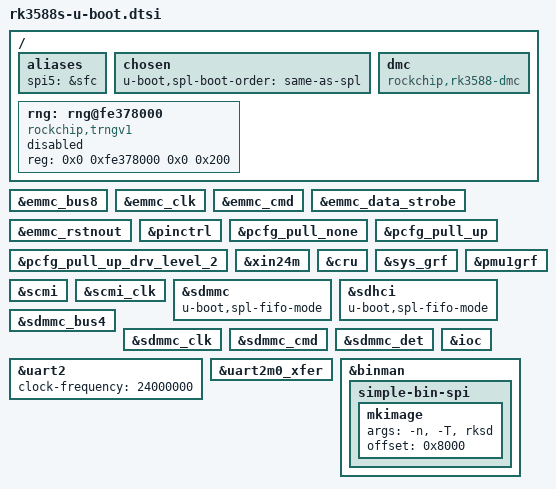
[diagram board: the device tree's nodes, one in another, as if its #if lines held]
// SPDX-License-Identifier: (GPL-2.0+ OR MIT)
/*
 * Copyright (c) 2022 Edgeble AI Technologies Pvt. Ltd.
 */

#include "rockchip-u-boot.dtsi"

/ {
	aliases {
		spi5 = &sfc;
	};

	chosen {
		u-boot,spl-boot-order = "same-as-spl", &sdmmc, &sdhci;
	};

	dmc {
		compatible = "rockchip,rk3588-dmc";
		bootph-all;
	};

	rng: rng@fe378000 {
		compatible = "rockchip,trngv1";
		reg = <0x0 0xfe378000 0x0 0x200>;
		status = "disabled";
	};
};

&emmc_bus8 {
	bootph-all;
};

&emmc_clk {
	bootph-all;
};

&emmc_cmd {
	bootph-all;
};

&emmc_data_strobe {
	bootph-all;
};

&emmc_rstnout {
	bootph-all;
};

&pinctrl {
	bootph-all;
};

&pcfg_pull_none {
	bootph-all;
};

&pcfg_pull_up_drv_level_2 {
	bootph-all;
};

&pcfg_pull_up {
	bootph-all;
};

&xin24m {
	bootph-all;
};

&cru {
	bootph-pre-ram;
};

&sys_grf {
	bootph-pre-ram;
};

&pmu1grf {
	bootph-all;
};

&scmi {
	bootph-pre-ram;
};

&scmi_clk {
	bootph-pre-ram;
};

&sdmmc {
	bootph-all;
	u-boot,spl-fifo-mode;
};

&sdhci {
	bootph-all;
	u-boot,spl-fifo-mode;
};

&sdmmc_bus4 {
	bootph-all;
};

&sdmmc_clk {
	bootph-all;
};

&sdmmc_cmd {
	bootph-all;
};

&sdmmc_det {
	bootph-all;
};

&uart2 {
	bootph-pre-ram;
	clock-frequency = <24000000>;
};

&uart2m0_xfer {
	bootph-all;
};

&ioc {
	bootph-pre-ram;
};

#ifdef CONFIG_ROCKCHIP_SPI_IMAGE
&binman {
	simple-bin-spi {
		mkimage {
			args = "-n", CONFIG_SYS_SOC, "-T", "rksd";
			offset = <0x8000>;
		};
	};
};
#endif
